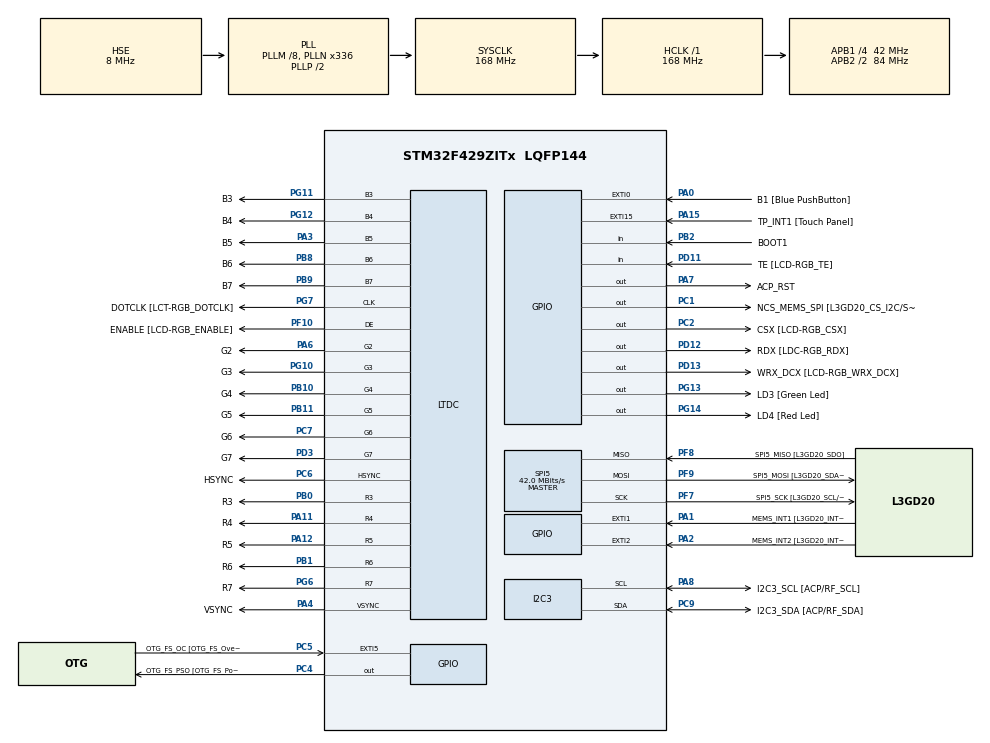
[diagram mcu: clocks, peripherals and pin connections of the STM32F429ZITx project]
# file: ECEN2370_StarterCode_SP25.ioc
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Mcu.Family=STM32F4
Mcu.Name=STM32F429ZITx
Mcu.Package=LQFP144
NVIC.PriorityGroup=NVIC_PRIORITYGROUP_0
NVIC.TIM2_IRQn=true\:0\:0\:false\:false\:true\:true\:true\:true
PA0/WKUP.GPIO_Label=B1 [Blue PushButton]
PA0/WKUP.GPIO_ModeDefaultEXTI=GPIO_MODE_EVT_RISING
PA0/WKUP.GPIO_PuPd=GPIO_NOPULL
PA0/WKUP.Signal=GPXTI0
PA1.GPIO_Label=MEMS_INT1 [L3GD20_INT1]
PA1.GPIO_ModeDefaultEXTI=GPIO_MODE_EVT_RISING
PA1.GPIO_PuPd=GPIO_NOPULL
PA1.Signal=GPXTI1
PA10.GPIO_Label=STLINK_TX [STM32F103CBT6_PA2]
PA10.Signal=USART1_RX
PA11.GPIO_Label=R4
PA11.GPIO_Mode=GPIO_MODE_AF_PP
PA11.GPIO_PuPd=GPIO_NOPULL
PA11.GPIO_Speed=GPIO_SPEED_FREQ_LOW
PA11.Mode=RGB565
PA11.Signal=LTDC_R4
PA12.GPIO_Label=R5
PA12.GPIO_Mode=GPIO_MODE_AF_PP
PA12.GPIO_PuPd=GPIO_NOPULL
PA12.GPIO_Speed=GPIO_SPEED_FREQ_LOW
PA12.Mode=RGB565
PA12.Signal=LTDC_R5
PA13.GPIO_Label=SWDIO
PA13.Signal=SYS_JTMS-SWDIO
PA14.GPIO_Label=SWCLK
PA14.Signal=SYS_JTCK-SWCLK
PA15.GPIO_Label=TP_INT1 [Touch Panel]
PA15.GPIO_ModeDefaultEXTI=GPIO_MODE_EVT_RISING
PA15.GPIO_PuPd=GPIO_NOPULL
PA15.Signal=GPXTI15
PA2.GPIO_Label=MEMS_INT2 [L3GD20_INT2]
PA2.GPIO_ModeDefaultEXTI=GPIO_MODE_EVT_RISING
PA2.GPIO_PuPd=GPIO_NOPULL
PA2.Signal=GPXTI2
PA3.GPIO_Label=B5
PA3.GPIO_Mode=GPIO_MODE_AF_PP
PA3.GPIO_PuPd=GPIO_NOPULL
PA3.GPIO_Speed=GPIO_SPEED_FREQ_LOW
PA3.Mode=RGB565
PA3.Signal=LTDC_B5
PA4.GPIO_Label=VSYNC
PA4.GPIO_Mode=GPIO_MODE_AF_PP
PA4.GPIO_PuPd=GPIO_NOPULL
PA4.GPIO_Speed=GPIO_SPEED_FREQ_LOW
PA4.Mode=RGB565
PA4.Signal=LTDC_VSYNC
PA6.GPIO_Label=G2
PA6.GPIO_Mode=GPIO_MODE_AF_PP
PA6.GPIO_PuPd=GPIO_NOPULL
PA6.GPIO_Speed=GPIO_SPEED_FREQ_LOW
PA6.Mode=RGB565
PA6.Signal=LTDC_G2
PA7.GPIO_Label=ACP_RST
PA7.GPIO_Mode=GPIO_MODE_OUTPUT_PP
PA7.GPIO_PuPd=GPIO_NOPULL
PA7.GPIO_Speed=GPIO_SPEED_FREQ_LOW
PA7.Signal=GPIO_Output
PA8.GPIO_Label=I2C3_SCL [ACP/RF_SCL]
PA8.GPIO_Mode=GPIO_MODE_AF_OD
PA8.GPIO_PuPd=GPIO_NOPULL
PA8.GPIO_Speed=GPIO_SPEED_FREQ_LOW
PA8.Mode=I2C
PA8.Signal=I2C3_SCL
PA9.GPIO_Label=STLINK_RX [STM32F103CBT6_PA3]
PA9.Signal=USART1_TX
PB0.GPIO_Label=R3
PB0.GPIO_Mode=GPIO_MODE_AF_PP
PB0.GPIO_PuPd=GPIO_NOPULL
PB0.GPIO_Speed=GPIO_SPEED_FREQ_LOW
PB0.Mode=RGB565
PB0.Signal=LTDC_R3
PB1.GPIO_Label=R6
PB1.GPIO_Mode=GPIO_MODE_AF_PP
PB1.GPIO_PuPd=GPIO_NOPULL
PB1.GPIO_Speed=GPIO_SPEED_FREQ_LOW
PB1.Mode=RGB565
PB1.Signal=LTDC_R6
PB10.GPIO_Label=G4
PB10.GPIO_Mode=GPIO_MODE_AF_PP
PB10.GPIO_PuPd=GPIO_NOPULL
PB10.GPIO_Speed=GPIO_SPEED_FREQ_LOW
PB10.Mode=RGB565
PB10.Signal=LTDC_G4
PB11.GPIO_Label=G5
PB11.GPIO_Mode=GPIO_MODE_AF_PP
PB11.GPIO_PuPd=GPIO_NOPULL
PB11.GPIO_Speed=GPIO_SPEED_FREQ_LOW
PB11.Mode=RGB565
PB11.Signal=LTDC_G5
PB12.GPIO_Label=OTG_HS_ID
PB12.GPIO_Mode=GPIO_MODE_AF_PP
PB12.GPIO_PuPd=GPIO_NOPULL
PB12.GPIO_Speed=GPIO_SPEED_FREQ_LOW
PB12.Signal=USB_OTG_HS_ID
PB13.GPIO_Label=VBUS_HS
PB13.GPIO_Mode=GPIO_MODE_INPUT
PB13.GPIO_PuPd=GPIO_NOPULL
PB13.Signal=USB_OTG_HS_VBUS
PB14.GPIO_Label=OTG_HS_DM
PB14.GPIO_Mode=GPIO_MODE_AF_PP
PB14.GPIO_PuPd=GPIO_NOPULL
PB14.GPIO_Speed=GPIO_SPEED_FREQ_LOW
PB14.Signal=USB_OTG_HS_DM
PB15.GPIO_Label=OTG_HS_DP
PB15.GPIO_Mode=GPIO_MODE_AF_PP
PB15.GPIO_PuPd=GPIO_NOPULL
PB15.GPIO_Speed=GPIO_SPEED_FREQ_LOW
PB15.Signal=USB_OTG_HS_DP
PB2/BOOT1.GPIO_Label=BOOT1
PB2/BOOT1.GPIO_Mode=GPIO_MODE_INPUT
PB2/BOOT1.GPIO_PuPd=GPIO_NOPULL
PB2/BOOT1.Signal=GPIO_Input
PB5.GPIO_Label=SDCKE1
PB5.GPIO_Mode=GPIO_MODE_AF_PP
PB5.GPIO_PuPd=GPIO_NOPULL
PB5.GPIO_Speed=GPIO_SPEED_FREQ_VERY_HIGH
PB5.Signal=FMC_SDCKE1
PB6.GPIO_Label=SDNE1 [SDRAM_CS]
PB6.GPIO_Mode=GPIO_MODE_AF_PP
PB6.GPIO_PuPd=GPIO_NOPULL
PB6.GPIO_Speed=GPIO_SPEED_FREQ_VERY_HIGH
PB6.Signal=FMC_SDNE1
PB8.GPIO_Label=B6
PB8.GPIO_Mode=GPIO_MODE_AF_PP
PB8.GPIO_PuPd=GPIO_NOPULL
PB8.GPIO_Speed=GPIO_SPEED_FREQ_LOW
PB8.Mode=RGB565
PB8.Signal=LTDC_B6
PB9.GPIO_Label=B7
PB9.GPIO_Mode=GPIO_MODE_AF_PP
PB9.GPIO_PuPd=GPIO_NOPULL
PB9.GPIO_Speed=GPIO_SPEED_FREQ_LOW
PB9.Mode=RGB565
PB9.Signal=LTDC_B7
PC0.GPIO_Label=SDNWE
PC0.GPIO_Mode=GPIO_MODE_AF_PP
PC0.GPIO_PuPd=GPIO_NOPULL
PC0.GPIO_Speed=GPIO_SPEED_FREQ_VERY_HIGH
PC0.Signal=FMC_SDNWE
PC1.GPIO_Label=NCS_MEMS_SPI [L3GD20_CS_I2C/SPI]
PC1.GPIO_Mode=GPIO_MODE_OUTPUT_PP
PC1.GPIO_PuPd=GPIO_NOPULL
PC1.GPIO_Speed=GPIO_SPEED_FREQ_LOW
PC1.Signal=GPIO_Output
PC10.GPIO_Label=R2
PC10.GPIO_Mode=GPIO_MODE_AF_PP
PC10.GPIO_PuPd=GPIO_NOPULL
PC10.GPIO_Speed=GPIO_SPEED_FREQ_LOW
PC10.Signal=LTDC_R2
PC14/OSC32_IN.GPIO_Label=PC14-OSC32_IN
PC14/OSC32_IN.Signal=RCC_OSC32_IN
PC15/OSC32_OUT.GPIO_Label=PC15-OSC32_OUT
PC15/OSC32_OUT.Signal=RCC_OSC32_OUT
PC2.GPIO_Label=CSX [LCD-RGB_CSX]
PC2.GPIO_Mode=GPIO_MODE_OUTPUT_PP
PC2.GPIO_PuPd=GPIO_NOPULL
PC2.GPIO_Speed=GPIO_SPEED_FREQ_LOW
PC2.Signal=GPIO_Output
PC4.GPIO_Label=OTG_FS_PSO [OTG_FS_PowerSwitchOn]
PC4.GPIO_Mode=GPIO_MODE_OUTPUT_PP
PC4.GPIO_PuPd=GPIO_NOPULL
PC4.GPIO_Speed=GPIO_SPEED_FREQ_LOW
PC4.Signal=GPIO_Output
PC5.GPIO_Label=OTG_FS_OC [OTG_FS_OverCurrent]
PC5.GPIO_ModeDefaultEXTI=GPIO_MODE_EVT_RISING
PC5.Signal=GPXTI5
PC6.GPIO_Label=HSYNC
PC6.GPIO_Mode=GPIO_MODE_AF_PP
PC6.GPIO_PuPd=GPIO_NOPULL
PC6.GPIO_Speed=GPIO_SPEED_FREQ_LOW
PC6.Mode=RGB565
PC6.Signal=LTDC_HSYNC
PC7.GPIO_Label=G6
PC7.GPIO_Mode=GPIO_MODE_AF_PP
PC7.GPIO_PuPd=GPIO_NOPULL
PC7.GPIO_Speed=GPIO_SPEED_FREQ_LOW
PC7.Mode=RGB565
PC7.Signal=LTDC_G6
PC9.GPIO_Label=I2C3_SDA [ACP/RF_SDA]
PC9.GPIO_Mode=GPIO_MODE_AF_OD
PC9.GPIO_PuPd=GPIO_NOPULL
PC9.GPIO_Speed=GPIO_SPEED_FREQ_LOW
PC9.Mode=I2C
PC9.Signal=I2C3_SDA
PD0.GPIO_Label=D2
PD0.GPIO_Mode=GPIO_MODE_AF_PP
PD0.GPIO_PuPd=GPIO_NOPULL
PD0.GPIO_Speed=GPIO_SPEED_FREQ_VERY_HIGH
PD0.Signal=FMC_D2_DA2
PD1.GPIO_Label=D3
PD1.GPIO_Mode=GPIO_MODE_AF_PP
PD1.GPIO_PuPd=GPIO_NOPULL
PD1.GPIO_Speed=GPIO_SPEED_FREQ_VERY_HIGH
PD1.Signal=FMC_D3_DA3
PD10.GPIO_Label=D15
PD10.GPIO_Mode=GPIO_MODE_AF_PP
PD10.GPIO_PuPd=GPIO_NOPULL
PD10.GPIO_Speed=GPIO_SPEED_FREQ_VERY_HIGH
PD10.Signal=FMC_D15_DA15
PD11.GPIO_Label=TE [LCD-RGB_TE]
PD11.GPIO_Mode=GPIO_MODE_INPUT
PD11.GPIO_PuPd=GPIO_NOPULL
PD11.Signal=GPIO_Input
PD12.GPIO_Label=RDX [LDC-RGB_RDX]
PD12.GPIO_Mode=GPIO_MODE_OUTPUT_PP
PD12.GPIO_PuPd=GPIO_NOPULL
PD12.GPIO_Speed=GPIO_SPEED_FREQ_LOW
PD12.Signal=GPIO_Output
PD13.GPIO_Label=WRX_DCX [LCD-RGB_WRX_DCX]
PD13.GPIO_Mode=GPIO_MODE_OUTPUT_PP
PD13.GPIO_PuPd=GPIO_NOPULL
PD13.GPIO_Speed=GPIO_SPEED_FREQ_LOW
PD13.Signal=GPIO_Output
PD14.GPIO_Label=D0
PD14.GPIO_Mode=GPIO_MODE_AF_PP
PD14.GPIO_PuPd=GPIO_NOPULL
PD14.GPIO_Speed=GPIO_SPEED_FREQ_VERY_HIGH
PD14.Signal=FMC_D0_DA0
PD15.GPIO_Label=D1
PD15.GPIO_Mode=GPIO_MODE_AF_PP
PD15.GPIO_PuPd=GPIO_NOPULL
PD15.GPIO_Speed=GPIO_SPEED_FREQ_VERY_HIGH
PD15.Signal=FMC_D1_DA1
PD3.GPIO_Label=G7
PD3.GPIO_Mode=GPIO_MODE_AF_PP
PD3.GPIO_PuPd=GPIO_NOPULL
PD3.GPIO_Speed=GPIO_SPEED_FREQ_LOW
PD3.Mode=RGB565
PD3.Signal=LTDC_G7
PD6.GPIO_Label=B2
PD6.GPIO_Mode=GPIO_MODE_AF_PP
PD6.GPIO_PuPd=GPIO_NOPULL
PD6.GPIO_Speed=GPIO_SPEED_FREQ_LOW
PD6.Signal=LTDC_B2
PD8.GPIO_Label=D13
PD8.GPIO_Mode=GPIO_MODE_AF_PP
PD8.GPIO_PuPd=GPIO_NOPULL
PD8.GPIO_Speed=GPIO_SPEED_FREQ_VERY_HIGH
PD8.Signal=FMC_D13_DA13
PD9.GPIO_Label=D14
PD9.GPIO_Mode=GPIO_MODE_AF_PP
PD9.GPIO_PuPd=GPIO_NOPULL
PD9.GPIO_Speed=GPIO_SPEED_FREQ_VERY_HIGH
PD9.Signal=FMC_D14_DA14
PE0.GPIO_Label=NBL0 [SDRAM_LDQM]
PE0.GPIO_Mode=GPIO_MODE_AF_PP
PE0.GPIO_PuPd=GPIO_NOPULL
PE0.GPIO_Speed=GPIO_SPEED_FREQ_VERY_HIGH
PE0.Signal=FMC_NBL0
PE1.GPIO_Label=NBL1 [SDRAM_UDQM]
PE1.GPIO_Mode=GPIO_MODE_AF_PP
PE1.GPIO_PuPd=GPIO_NOPULL
PE1.GPIO_Speed=GPIO_SPEED_FREQ_VERY_HIGH
PE1.Signal=FMC_NBL1
PE10.GPIO_Label=D7
PE10.GPIO_Mode=GPIO_MODE_AF_PP
PE10.GPIO_PuPd=GPIO_NOPULL
PE10.GPIO_Speed=GPIO_SPEED_FREQ_VERY_HIGH
PE10.Signal=FMC_D7_DA7
PE11.GPIO_Label=D8
PE11.GPIO_Mode=GPIO_MODE_AF_PP
PE11.GPIO_PuPd=GPIO_NOPULL
PE11.GPIO_Speed=GPIO_SPEED_FREQ_VERY_HIGH
PE11.Signal=FMC_D8_DA8
PE12.GPIO_Label=D9
PE12.GPIO_Mode=GPIO_MODE_AF_PP
PE12.GPIO_PuPd=GPIO_NOPULL
PE12.GPIO_Speed=GPIO_SPEED_FREQ_VERY_HIGH
PE12.Signal=FMC_D9_DA9
PE13.GPIO_Label=D10
PE13.GPIO_Mode=GPIO_MODE_AF_PP
PE13.GPIO_PuPd=GPIO_NOPULL
PE13.GPIO_Speed=GPIO_SPEED_FREQ_VERY_HIGH
PE13.Signal=FMC_D10_DA10
PE14.GPIO_Label=D11
PE14.GPIO_Mode=GPIO_MODE_AF_PP
PE14.GPIO_PuPd=GPIO_NOPULL
PE14.GPIO_Speed=GPIO_SPEED_FREQ_VERY_HIGH
PE14.Signal=FMC_D11_DA11
PE15.GPIO_Label=D12
PE15.GPIO_Mode=GPIO_MODE_AF_PP
PE15.GPIO_PuPd=GPIO_NOPULL
PE15.GPIO_Speed=GPIO_SPEED_FREQ_VERY_HIGH
PE15.Signal=FMC_D12_DA12
PE7.GPIO_Label=D4
PE7.GPIO_Mode=GPIO_MODE_AF_PP
PE7.GPIO_PuPd=GPIO_NOPULL
PE7.GPIO_Speed=GPIO_SPEED_FREQ_VERY_HIGH
PE7.Signal=FMC_D4_DA4
PE8.GPIO_Label=D5
PE8.GPIO_Mode=GPIO_MODE_AF_PP
PE8.GPIO_PuPd=GPIO_NOPULL
PE8.GPIO_Speed=GPIO_SPEED_FREQ_VERY_HIGH
PE8.Signal=FMC_D5_DA5
PE9.GPIO_Label=D6
PE9.GPIO_Mode=GPIO_MODE_AF_PP
PE9.GPIO_PuPd=GPIO_NOPULL
PE9.GPIO_Speed=GPIO_SPEED_FREQ_VERY_HIGH
PE9.Signal=FMC_D6_DA6
PF0.GPIO_Label=A0
PF0.GPIO_Mode=GPIO_MODE_AF_PP
PF0.GPIO_PuPd=GPIO_NOPULL
PF0.GPIO_Speed=GPIO_SPEED_FREQ_VERY_HIGH
PF0.Signal=FMC_A0
PF1.GPIO_Label=A1
PF1.GPIO_Mode=GPIO_MODE_AF_PP
PF1.GPIO_PuPd=GPIO_NOPULL
PF1.GPIO_Speed=GPIO_SPEED_FREQ_VERY_HIGH
PF1.Signal=FMC_A1
PF10.GPIO_Label=ENABLE [LCD-RGB_ENABLE]
PF10.GPIO_Mode=GPIO_MODE_AF_PP
PF10.GPIO_PuPd=GPIO_NOPULL
PF10.GPIO_Speed=GPIO_SPEED_FREQ_LOW
PF10.Mode=RGB565
PF10.Signal=LTDC_DE
PF11.GPIO_Label=SDNRAS
PF11.GPIO_Mode=GPIO_MODE_AF_PP
PF11.GPIO_PuPd=GPIO_NOPULL
PF11.GPIO_Speed=GPIO_SPEED_FREQ_VERY_HIGH
PF11.Signal=FMC_SDNRAS
PF12.GPIO_Label=A6
PF12.GPIO_Mode=GPIO_MODE_AF_PP
PF12.GPIO_PuPd=GPIO_NOPULL
PF12.GPIO_Speed=GPIO_SPEED_FREQ_VERY_HIGH
PF12.Signal=FMC_A6
PF13.GPIO_Label=A7
PF13.GPIO_Mode=GPIO_MODE_AF_PP
PF13.GPIO_PuPd=GPIO_NOPULL
PF13.GPIO_Speed=GPIO_SPEED_FREQ_VERY_HIGH
PF13.Signal=FMC_A7
PF14.GPIO_Label=A8
PF14.GPIO_Mode=GPIO_MODE_AF_PP
PF14.GPIO_PuPd=GPIO_NOPULL
PF14.GPIO_Speed=GPIO_SPEED_FREQ_VERY_HIGH
PF14.Signal=FMC_A8
PF15.GPIO_Label=A9
PF15.GPIO_Mode=GPIO_MODE_AF_PP
PF15.GPIO_PuPd=GPIO_NOPULL
PF15.GPIO_Speed=GPIO_SPEED_FREQ_VERY_HIGH
PF15.Signal=FMC_A9
PF2.GPIO_Label=A2
PF2.GPIO_Mode=GPIO_MODE_AF_PP
PF2.GPIO_PuPd=GPIO_NOPULL
PF2.GPIO_Speed=GPIO_SPEED_FREQ_VERY_HIGH
PF2.Signal=FMC_A2
PF3.GPIO_Label=A3
PF3.GPIO_Mode=GPIO_MODE_AF_PP
PF3.GPIO_PuPd=GPIO_NOPULL
PF3.GPIO_Speed=GPIO_SPEED_FREQ_VERY_HIGH
PF3.Signal=FMC_A3
PF4.GPIO_Label=A4
PF4.GPIO_Mode=GPIO_MODE_AF_PP
PF4.GPIO_PuPd=GPIO_NOPULL
PF4.GPIO_Speed=GPIO_SPEED_FREQ_VERY_HIGH
PF4.Signal=FMC_A4
PF5.GPIO_Label=A5
PF5.GPIO_Mode=GPIO_MODE_AF_PP
PF5.GPIO_PuPd=GPIO_NOPULL
PF5.GPIO_Speed=GPIO_SPEED_FREQ_VERY_HIGH
PF5.Signal=FMC_A5
PF7.GPIO_Label=SPI5_SCK [L3GD20_SCL/SPC]
PF7.GPIO_Mode=GPIO_MODE_AF_PP
PF7.GPIO_PuPd=GPIO_NOPULL
PF7.GPIO_Speed=GPIO_SPEED_FREQ_LOW
PF7.Mode=Full_Duplex_Master
PF7.Signal=SPI5_SCK
PF8.GPIO_Label=SPI5_MISO [L3GD20_SDO]
PF8.GPIO_Mode=GPIO_MODE_AF_PP
PF8.GPIO_PuPd=GPIO_NOPULL
PF8.GPIO_Speed=GPIO_SPEED_FREQ_LOW
PF8.Mode=Full_Duplex_Master
PF8.Signal=SPI5_MISO
PF9.GPIO_Label=SPI5_MOSI [L3GD20_SDA/SDI/SDO]
PF9.GPIO_Mode=GPIO_MODE_AF_PP
PF9.GPIO_PuPd=GPIO_NOPULL
PF9.GPIO_Speed=GPIO_SPEED_FREQ_LOW
PF9.Mode=Full_Duplex_Master
PF9.Signal=SPI5_MOSI
PG0.GPIO_Label=A10
PG0.GPIO_Mode=GPIO_MODE_AF_PP
PG0.GPIO_PuPd=GPIO_NOPULL
PG0.GPIO_Speed=GPIO_SPEED_FREQ_VERY_HIGH
PG0.Signal=FMC_A10
PG1.GPIO_Label=A11
PG1.GPIO_Mode=GPIO_MODE_AF_PP
PG1.GPIO_PuPd=GPIO_NOPULL
PG1.GPIO_Speed=GPIO_SPEED_FREQ_VERY_HIGH
PG1.Signal=FMC_A11
PG10.GPIO_Label=G3
PG10.GPIO_Mode=GPIO_MODE_AF_PP
PG10.GPIO_PuPd=GPIO_NOPULL
PG10.GPIO_Speed=GPIO_SPEED_FREQ_LOW
PG10.Mode=RGB565
PG10.Signal=LTDC_G3
PG11.GPIO_Label=B3
PG11.GPIO_Mode=GPIO_MODE_AF_PP
PG11.GPIO_PuPd=GPIO_NOPULL
PG11.GPIO_Speed=GPIO_SPEED_FREQ_LOW
PG11.Mode=RGB565
PG11.Signal=LTDC_B3
PG12.GPIO_Label=B4
PG12.GPIO_Mode=GPIO_MODE_AF_PP
PG12.GPIO_PuPd=GPIO_NOPULL
PG12.GPIO_Speed=GPIO_SPEED_FREQ_LOW
PG12.Mode=RGB565
PG12.Signal=LTDC_B4
PG13.GPIO_Label=LD3 [Green Led]
PG13.GPIO_Mode=GPIO_MODE_OUTPUT_PP
PG13.GPIO_PuPd=GPIO_NOPULL
PG13.GPIO_Speed=GPIO_SPEED_FREQ_LOW
PG13.Signal=GPIO_Output
PG14.GPIO_Label=LD4 [Red Led]
PG14.GPIO_Mode=GPIO_MODE_OUTPUT_PP
PG14.GPIO_PuPd=GPIO_NOPULL
PG14.GPIO_Speed=GPIO_SPEED_FREQ_LOW
PG14.Signal=GPIO_Output
PG15.GPIO_Label=SDNCAS
PG15.GPIO_Mode=GPIO_MODE_AF_PP
PG15.GPIO_PuPd=GPIO_NOPULL
PG15.GPIO_Speed=GPIO_SPEED_FREQ_VERY_HIGH
PG15.Signal=FMC_SDNCAS
PG4.GPIO_Label=BA0
PG4.GPIO_Mode=GPIO_MODE_AF_PP
PG4.GPIO_PuPd=GPIO_NOPULL
PG4.GPIO_Speed=GPIO_SPEED_FREQ_VERY_HIGH
PG4.Signal=FMC_A14_BA0
PG5.GPIO_Label=BA1
PG5.GPIO_Mode=GPIO_MODE_AF_PP
PG5.GPIO_PuPd=GPIO_NOPULL
PG5.GPIO_Speed=GPIO_SPEED_FREQ_VERY_HIGH
PG5.Signal=FMC_A15_BA1
PG6.GPIO_Label=R7
PG6.GPIO_Mode=GPIO_MODE_AF_PP
PG6.GPIO_PuPd=GPIO_NOPULL
PG6.GPIO_Speed=GPIO_SPEED_FREQ_LOW
PG6.Mode=RGB565
PG6.Signal=LTDC_R7
PG7.GPIO_Label=DOTCLK [LCT-RGB_DOTCLK]
PG7.GPIO_Mode=GPIO_MODE_AF_PP
PG7.GPIO_PuPd=GPIO_NOPULL
PG7.GPIO_Speed=GPIO_SPEED_FREQ_LOW
PG7.Mode=RGB565
PG7.Signal=LTDC_CLK
PG8.GPIO_Label=SDCLK
PG8.GPIO_Mode=GPIO_MODE_AF_PP
PG8.GPIO_PuPd=GPIO_NOPULL
PG8.GPIO_Speed=GPIO_SPEED_FREQ_VERY_HIGH
PG8.Signal=FMC_SDCLK
PH0/OSC_IN.GPIO_Label=PH0-OSC_IN
PH0/OSC_IN.Mode=HSE-External-Oscillator
PH0/OSC_IN.Signal=RCC_OSC_IN
PH1/OSC_OUT.GPIO_Label=PH1-OSC_OUT
PH1/OSC_OUT.Mode=HSE-External-Oscillator
PH1/OSC_OUT.Signal=RCC_OSC_OUT
ProjectManager.HeapSize=0x200
ProjectManager.StackSize=0x400
ProjectManager.TargetToolchain=STM32CubeIDE
RCC.48MHZClocksFreq_Value=48000000
RCC.AHBFreq_Value=168000000
RCC.APB1CLKDivider=RCC_HCLK_DIV4
RCC.APB1Freq_Value=42000000
RCC.APB1TimFreq_Value=84000000
RCC.APB2CLKDivider=RCC_HCLK_DIV2
RCC.APB2Freq_Value=84000000
RCC.APB2TimFreq_Value=168000000
RCC.CortexFreq_Value=168000000
RCC.HCLKFreq_Value=168000000
RCC.HSE_VALUE=8000000
RCC.HSI_VALUE=16000000
RCC.LSE_VALUE=32768
RCC.PLLM=8
RCC.PLLN=336
RCC.PLLQ=7
RCC.PLLSAIDivR=RCC_PLLSAIDIVR_16
RCC.PLLSAIN=200
RCC.PLLSourceVirtual=RCC_PLLSOURCE_HSE
RCC.SYSCLKFreq_VALUE=168000000
RCC.SYSCLKSource=RCC_SYSCLKSOURCE_PLLCLK
RCC.VCOOutputFreq_Value=336000000
SH.FMC_A0.0=FMC_A0
SH.FMC_A1.0=FMC_A1
SH.FMC_A10.0=FMC_A10
SH.FMC_A11.0=FMC_A11
SH.FMC_A14_BA0.0=FMC_BA0
SH.FMC_A15_BA1.0=FMC_BA1
SH.FMC_A2.0=FMC_A2
SH.FMC_A3.0=FMC_A3
SH.FMC_A4.0=FMC_A4
SH.FMC_A5.0=FMC_A5
SH.FMC_A6.0=FMC_A6
SH.FMC_A7.0=FMC_A7
SH.FMC_A8.0=FMC_A8
SH.FMC_A9.0=FMC_A9
SH.FMC_D0_DA0.0=FMC_D0
SH.FMC_D10_DA10.0=FMC_D10
SH.FMC_D11_DA11.0=FMC_D11
SH.FMC_D12_DA12.0=FMC_D12
SH.FMC_D13_DA13.0=FMC_D13
SH.FMC_D14_DA14.0=FMC_D14
SH.FMC_D15_DA15.0=FMC_D15
SH.FMC_D1_DA1.0=FMC_D1
SH.FMC_D2_DA2.0=FMC_D2
SH.FMC_D3_DA3.0=FMC_D3
SH.FMC_D4_DA4.0=FMC_D4
SH.FMC_D5_DA5.0=FMC_D5
SH.FMC_D6_DA6.0=FMC_D6
SH.FMC_D7_DA7.0=FMC_D7
SH.FMC_D8_DA8.0=FMC_D8
SH.FMC_D9_DA9.0=FMC_D9
SH.FMC_NBL0.0=FMC_NBL0
SH.FMC_NBL1.0=FMC_NBL1
SH.FMC_SDCLK.0=FMC_SDCLK
SH.FMC_SDNCAS.0=FMC_SDNCAS
SH.FMC_SDNRAS.0=FMC_SDNRAS
SH.FMC_SDNWE.0=FMC_SDNWE
SPI5.CalculateBaudRate=42.0 MBits/s
SPI5.Direction=SPI_DIRECTION_2LINES
SPI5.Mode=SPI_MODE_MASTER
SPI5.VirtualType=VM_MASTER
TIM2.Period=199
TIM2.Prescaler=8399
VP_RNG_VS_RNG.Mode=RNG_Activate
VP_TIM2_VS_ClockSourceINT.Mode=Internal
board=STM32F429I-DISC1

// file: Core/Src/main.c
/* USER CODE BEGIN Header */
/**
  ******************************************************************************
  * @file           : main.c
  * @brief          : Main program body
  ******************************************************************************
  * @attention
  *
  * Copyright (c) 2025 STMicroelectronics.
  * All rights reserved.
  *
  * This software is licensed AS-IS.
  *
  ******************************************************************************
  */
/* USER CODE END Header */
#include "main.h"
#include "board.h"
#include "game.h"
#include "ui.h"
#include "ApplicationCode.h"
#include "LCD_Driver.h"
#include "input.h"
#include "ai.h"

I2C_HandleTypeDef hi2c3;

LTDC_HandleTypeDef hltdc;

RNG_HandleTypeDef hrng;

SPI_HandleTypeDef hspi5;

TIM_HandleTypeDef htim2;

/* USER CODE BEGIN PV */
extern uint8_t  gameOver;
extern uint32_t startTime;
extern uint8_t  winsP1;
extern uint8_t  winsP2;

/* USER CODE END PV */

void SystemClock_Config(void);
static void MX_GPIO_Init(void);
static void MX_LTDC_Init(void);
static void MX_RNG_Init(void);
static void MX_TIM2_Init(void);
static void MX_SPI5_Init(void);
static void MX_I2C3_Init(void);

  volatile uint8_t flag_touchScan  = 0;   /* set every 20 ms  */
  volatile uint8_t flag_statusBar  = 0;   /* set every ≈240 ms*/
  #define MOVE_INITIAL_DELAY   300u     /* 0.3 s */
  #define MOVE_REPEAT_DELAY    120u     /* 0.12 s */

  static void ProcessTouchAndMoveSelector(void);

  static void ProcessTouchAndMoveSelector(void)
  {
      static uint8_t  touchHeld    = 0;
      static uint32_t nextMoveTick = 0;
      static uint8_t  dropHeld     = 0;

      STMPE811_TouchData t;
      uint8_t st = returnTouchStateAndLocation(&t);

      /* -------- left / right sweep -------- */
      if (st == STMPE811_State_Pressed)
      {
          t.x = LCD_PIXEL_WIDTH - 1 - t.x;

          if (HAL_GetTick() >= nextMoveTick)
          {
              if (t.x < LCD_PIXEL_WIDTH / 2)  { if (selectedCol > 0)        selectedCol--; }
              else                            { if (selectedCol < COLS - 1) selectedCol++; }

              nextMoveTick = HAL_GetTick() +
                             (touchHeld ? MOVE_REPEAT_DELAY : MOVE_INITIAL_DELAY);
              touchHeld = 1;
          }
      }
      else { touchHeld = 0; nextMoveTick = 0; }

      /* -------- push-button DROP --------- */
      if (IsDropPressed())
      {
          if (dropHeld == 0)
          {
              dropHeld = 1;
              int8_t row = DropToken(selectedCol);
              if (row >= 0)
              {
                  if (CheckWin(row, selectedCol))
                  {
                      if (currentPlayer == 1) { winsP1++; SetRoundResult(1); }
                      else                     { winsP2++; SetRoundResult(2); }
                      gameOver = 1;
                  }
                  else if (CheckDraw()) { SetRoundResult(0); gameOver = 1; }
                  else                  { currentPlayer = (currentPlayer == 1) ? 2 : 1; }
              }
          }
      }
      else dropHeld = 0;
  }

  int main(void)
  {
      HAL_Init();
      SystemClock_Config();
      MX_GPIO_Init();
      MX_LTDC_Init();
      MX_I2C3_Init();
      MX_RNG_Init();
      MX_TIM2_Init();
      MX_SPI5_Init();

      ApplicationInit();
      HAL_Delay(500);

      HAL_TIM_Base_Start_IT(&htim2);     /* 20 ms tick (PSC=8399, ARR=199) */

      ResetGame();
      winsP1 = winsP2 = 0;
      SetRoundResult(0);

      WaitForModeSelection();
      DrawBoard();
      DrawStatusBar();
      DrawHoverToken(selectedCol, currentPlayer);

      uint8_t  prevSelCol   = selectedCol;

      while (1)
      {
          if (flag_touchScan)
          {
              flag_touchScan = 0;
              ProcessTouchAndMoveSelector();
          }

          if (flag_statusBar)
          {
              flag_statusBar = 0;
              DrawStatusBar();
          }

          if (!gameOver && gameMode == 1 && currentPlayer == 2)
          {
              int8_t col = GetSmartAIMove();
              if (col >= 0)
              {
                  HAL_Delay(150);
                  int8_t row = DropToken(col);
                  if (CheckWin(row, col))            { winsP2++; SetRoundResult(2); gameOver = 1; }
                  else if (CheckDraw())              { SetRoundResult(0);          gameOver = 1; }
                  else                               { currentPlayer = 1; }
              }
          }

          if (prevSelCol != selectedCol)
          {
              ClearHoverToken(prevSelCol);
              DrawHoverToken(selectedCol, currentPlayer);
              prevSelCol = selectedCol;
          }

          if (gameOver)
          {
              DrawFinalScreen(GetElapsedTimeSeconds());
              WaitForRestartTap();

              ResetGame();
              SetRoundResult(0);
              DrawBoard();
              DrawStatusBar();
              DrawHoverToken(selectedCol, currentPlayer);

              prevSelCol   = selectedCol;

          }
      }
  }

void SystemClock_Config(void)
{
  RCC_OscInitTypeDef RCC_OscInitStruct = {0};
  RCC_ClkInitTypeDef RCC_ClkInitStruct = {0};

  /** Configure the main internal regulator output voltage
  */
  __HAL_RCC_PWR_CLK_ENABLE();
  __HAL_PWR_VOLTAGESCALING_CONFIG(PWR_REGULATOR_VOLTAGE_SCALE1);

  /** Initializes the RCC Oscillators according to the specified parameters
  * in the RCC_OscInitTypeDef structure.
  */
  RCC_OscInitStruct.OscillatorType = RCC_OSCILLATORTYPE_HSE;
  RCC_OscInitStruct.HSEState = RCC_HSE_ON;
  RCC_OscInitStruct.PLL.PLLState = RCC_PLL_ON;
  RCC_OscInitStruct.PLL.PLLSource = RCC_PLLSOURCE_HSE;
  RCC_OscInitStruct.PLL.PLLM = 8;
  RCC_OscInitStruct.PLL.PLLN = 336;
  RCC_OscInitStruct.PLL.PLLP = RCC_PLLP_DIV2;
  RCC_OscInitStruct.PLL.PLLQ = 7;
  if (HAL_RCC_OscConfig(&RCC_OscInitStruct) != HAL_OK)
  {
    Error_Handler();
  }

  /** Initializes the CPU, AHB and APB buses clocks
  */
  RCC_ClkInitStruct.ClockType = RCC_CLOCKTYPE_HCLK|RCC_CLOCKTYPE_SYSCLK
                              |RCC_CLOCKTYPE_PCLK1|RCC_CLOCKTYPE_PCLK2;
  RCC_ClkInitStruct.SYSCLKSource = RCC_SYSCLKSOURCE_PLLCLK;
  RCC_ClkInitStruct.AHBCLKDivider = RCC_SYSCLK_DIV1;
  RCC_ClkInitStruct.APB1CLKDivider = RCC_HCLK_DIV4;
  RCC_ClkInitStruct.APB2CLKDivider = RCC_HCLK_DIV2;

  if (HAL_RCC_ClockConfig(&RCC_ClkInitStruct, FLASH_LATENCY_5) != HAL_OK)
  {
    Error_Handler();
  }
}

static void MX_I2C3_Init(void)
{

  hi2c3.Instance = I2C3;
  hi2c3.Init.ClockSpeed = 100000;
  hi2c3.Init.DutyCycle = I2C_DUTYCYCLE_2;
  hi2c3.Init.OwnAddress1 = 0;
  hi2c3.Init.AddressingMode = I2C_ADDRESSINGMODE_7BIT;
  hi2c3.Init.DualAddressMode = I2C_DUALADDRESS_DISABLE;
  hi2c3.Init.OwnAddress2 = 0;
  hi2c3.Init.GeneralCallMode = I2C_GENERALCALL_DISABLE;
  hi2c3.Init.NoStretchMode = I2C_NOSTRETCH_DISABLE;
  if (HAL_I2C_Init(&hi2c3) != HAL_OK)
  {
    Error_Handler();
  }

  /** Configure Analogue filter
  */
  if (HAL_I2CEx_ConfigAnalogFilter(&hi2c3, I2C_ANALOGFILTER_ENABLE) != HAL_OK)
  {
    Error_Handler();
  }

  /** Configure Digital filter
  */
  if (HAL_I2CEx_ConfigDigitalFilter(&hi2c3, 0) != HAL_OK)
  {
    Error_Handler();
  }

}

static void MX_LTDC_Init(void)
{

  LTDC_LayerCfgTypeDef pLayerCfg = {0};
  LTDC_LayerCfgTypeDef pLayerCfg1 = {0};

  hltdc.Instance = LTDC;
  hltdc.Init.HSPolarity = LTDC_HSPOLARITY_AL;
  hltdc.Init.VSPolarity = LTDC_VSPOLARITY_AL;
  hltdc.Init.DEPolarity = LTDC_DEPOLARITY_AL;
  hltdc.Init.PCPolarity = LTDC_PCPOLARITY_IPC;
  hltdc.Init.HorizontalSync = 7;
  hltdc.Init.VerticalSync = 3;
  hltdc.Init.AccumulatedHBP = 14;
  hltdc.Init.AccumulatedVBP = 5;
  hltdc.Init.AccumulatedActiveW = 654;
  hltdc.Init.AccumulatedActiveH = 485;
  hltdc.Init.TotalWidth = 660;
  hltdc.Init.TotalHeigh = 487;
  hltdc.Init.Backcolor.Blue = 0;
  hltdc.Init.Backcolor.Green = 0;
  hltdc.Init.Backcolor.Red = 0;
  if (HAL_LTDC_Init(&hltdc) != HAL_OK)
  {
    Error_Handler();
  }
  pLayerCfg.WindowX0 = 0;
  pLayerCfg.WindowX1 = 0;
  pLayerCfg.WindowY0 = 0;
  pLayerCfg.WindowY1 = 0;
  pLayerCfg.PixelFormat = LTDC_PIXEL_FORMAT_ARGB8888;
  pLayerCfg.Alpha = 0;
  pLayerCfg.Alpha0 = 0;
  pLayerCfg.BlendingFactor1 = LTDC_BLENDING_FACTOR1_CA;
  pLayerCfg.BlendingFactor2 = LTDC_BLENDING_FACTOR2_CA;
  pLayerCfg.FBStartAdress = 0;
  pLayerCfg.ImageWidth = 0;
  pLayerCfg.ImageHeight = 0;
  pLayerCfg.Backcolor.Blue = 0;
  pLayerCfg.Backcolor.Green = 0;
  pLayerCfg.Backcolor.Red = 0;
  if (HAL_LTDC_ConfigLayer(&hltdc, &pLayerCfg, 0) != HAL_OK)
  {
    Error_Handler();
  }
  pLayerCfg1.WindowX0 = 0;
  pLayerCfg1.WindowX1 = 0;
  pLayerCfg1.WindowY0 = 0;
  pLayerCfg1.WindowY1 = 0;
  pLayerCfg1.PixelFormat = LTDC_PIXEL_FORMAT_ARGB8888;
  pLayerCfg1.Alpha = 0;
  pLayerCfg1.Alpha0 = 0;
  pLayerCfg1.BlendingFactor1 = LTDC_BLENDING_FACTOR1_CA;
  pLayerCfg1.BlendingFactor2 = LTDC_BLENDING_FACTOR2_CA;
  pLayerCfg1.FBStartAdress = 0;
  pLayerCfg1.ImageWidth = 0;
  pLayerCfg1.ImageHeight = 0;
  pLayerCfg1.Backcolor.Blue = 0;
  pLayerCfg1.Backcolor.Green = 0;
  pLayerCfg1.Backcolor.Red = 0;
  if (HAL_LTDC_ConfigLayer(&hltdc, &pLayerCfg1, 1) != HAL_OK)
  {
    Error_Handler();
  }

}

static void MX_RNG_Init(void)
{

  hrng.Instance = RNG;
  if (HAL_RNG_Init(&hrng) != HAL_OK)
  {
    Error_Handler();
  }

}

static void MX_SPI5_Init(void)
{

  /* SPI5 parameter configuration*/
  hspi5.Instance = SPI5;
  hspi5.Init.Mode = SPI_MODE_MASTER;
  hspi5.Init.Direction = SPI_DIRECTION_2LINES;
  hspi5.Init.DataSize = SPI_DATASIZE_8BIT;
  hspi5.Init.CLKPolarity = SPI_POLARITY_LOW;
  hspi5.Init.CLKPhase = SPI_PHASE_1EDGE;
  hspi5.Init.NSS = SPI_NSS_SOFT;
  hspi5.Init.BaudRatePrescaler = SPI_BAUDRATEPRESCALER_2;
  hspi5.Init.FirstBit = SPI_FIRSTBIT_MSB;
  hspi5.Init.TIMode = SPI_TIMODE_DISABLE;
  hspi5.Init.CRCCalculation = SPI_CRCCALCULATION_DISABLE;
  hspi5.Init.CRCPolynomial = 10;
  if (HAL_SPI_Init(&hspi5) != HAL_OK)
  {
    Error_Handler();
  }

}

static void MX_TIM2_Init(void)
{

  TIM_ClockConfigTypeDef sClockSourceConfig = {0};
  TIM_MasterConfigTypeDef sMasterConfig = {0};

  htim2.Instance = TIM2;
  htim2.Init.Prescaler = 8399;
  htim2.Init.CounterMode = TIM_COUNTERMODE_UP;
  htim2.Init.Period = 199;
  htim2.Init.ClockDivision = TIM_CLOCKDIVISION_DIV1;
  htim2.Init.AutoReloadPreload = TIM_AUTORELOAD_PRELOAD_DISABLE;
  if (HAL_TIM_Base_Init(&htim2) != HAL_OK)
  {
    Error_Handler();
  }
  sClockSourceConfig.ClockSource = TIM_CLOCKSOURCE_INTERNAL;
  if (HAL_TIM_ConfigClockSource(&htim2, &sClockSourceConfig) != HAL_OK)
  {
    Error_Handler();
  }
  sMasterConfig.MasterOutputTrigger = TIM_TRGO_RESET;
  sMasterConfig.MasterSlaveMode = TIM_MASTERSLAVEMODE_DISABLE;
  if (HAL_TIMEx_MasterConfigSynchronization(&htim2, &sMasterConfig) != HAL_OK)
  {
    Error_Handler();
  }

}

static void MX_GPIO_Init(void)
{
  GPIO_InitTypeDef GPIO_InitStruct = {0};

  /* GPIO Ports Clock Enable */
  __HAL_RCC_GPIOC_CLK_ENABLE();
  __HAL_RCC_GPIOF_CLK_ENABLE();
  __HAL_RCC_GPIOH_CLK_ENABLE();
  __HAL_RCC_GPIOA_CLK_ENABLE();
  __HAL_RCC_GPIOB_CLK_ENABLE();
  __HAL_RCC_GPIOG_CLK_ENABLE();
  __HAL_RCC_GPIOE_CLK_ENABLE();
  __HAL_RCC_GPIOD_CLK_ENABLE();

  /*Configure GPIO pin Output Level */
  HAL_GPIO_WritePin(GPIOC, NCS_MEMS_SPI_Pin|CSX_Pin|OTG_FS_PSO_Pin, GPIO_PIN_RESET);

  /*Configure GPIO pin Output Level */
  HAL_GPIO_WritePin(ACP_RST_GPIO_Port, ACP_RST_Pin, GPIO_PIN_RESET);

  /*Configure GPIO pin Output Level */
  HAL_GPIO_WritePin(GPIOD, RDX_Pin|WRX_DCX_Pin, GPIO_PIN_RESET);

  /*Configure GPIO pin Output Level */
  HAL_GPIO_WritePin(GPIOG, LD3_Pin|LD4_Pin, GPIO_PIN_RESET);

  /*Configure GPIO pins : A0_Pin A1_Pin A2_Pin A3_Pin
                           A4_Pin A5_Pin SDNRAS_Pin A6_Pin
                           A7_Pin A8_Pin A9_Pin */
  GPIO_InitStruct.Pin = A0_Pin|A1_Pin|A2_Pin|A3_Pin
                          |A4_Pin|A5_Pin|SDNRAS_Pin|A6_Pin
                          |A7_Pin|A8_Pin|A9_Pin;
  GPIO_InitStruct.Mode = GPIO_MODE_AF_PP;
  GPIO_InitStruct.Pull = GPIO_NOPULL;
  GPIO_InitStruct.Speed = GPIO_SPEED_FREQ_VERY_HIGH;
  GPIO_InitStruct.Alternate = GPIO_AF12_FMC;
  HAL_GPIO_Init(GPIOF, &GPIO_InitStruct);

  /*Configure GPIO pin : SDNWE_Pin */
  GPIO_InitStruct.Pin = SDNWE_Pin;
  GPIO_InitStruct.Mode = GPIO_MODE_AF_PP;
  GPIO_InitStruct.Pull = GPIO_NOPULL;
  GPIO_InitStruct.Speed = GPIO_SPEED_FREQ_VERY_HIGH;
  GPIO_InitStruct.Alternate = GPIO_AF12_FMC;
  HAL_GPIO_Init(SDNWE_GPIO_Port, &GPIO_InitStruct);

  /*Configure GPIO pins : NCS_MEMS_SPI_Pin CSX_Pin OTG_FS_PSO_Pin */
  GPIO_InitStruct.Pin = NCS_MEMS_SPI_Pin|CSX_Pin|OTG_FS_PSO_Pin;
  GPIO_InitStruct.Mode = GPIO_MODE_OUTPUT_PP;
  GPIO_InitStruct.Pull = GPIO_NOPULL;
  GPIO_InitStruct.Speed = GPIO_SPEED_FREQ_LOW;
  HAL_GPIO_Init(GPIOC, &GPIO_InitStruct);

  /*Configure GPIO pins : B1_Pin MEMS_INT1_Pin MEMS_INT2_Pin TP_INT1_Pin */
  GPIO_InitStruct.Pin = B1_Pin|MEMS_INT1_Pin|MEMS_INT2_Pin|TP_INT1_Pin;
  GPIO_InitStruct.Mode = GPIO_MODE_EVT_RISING;
  GPIO_InitStruct.Pull = GPIO_NOPULL;
  HAL_GPIO_Init(GPIOA, &GPIO_InitStruct);

  /*Configure GPIO pin : ACP_RST_Pin */
  GPIO_InitStruct.Pin = ACP_RST_Pin;
  GPIO_InitStruct.Mode = GPIO_MODE_OUTPUT_PP;
  GPIO_InitStruct.Pull = GPIO_NOPULL;
  GPIO_InitStruct.Speed = GPIO_SPEED_FREQ_LOW;
  HAL_GPIO_Init(ACP_RST_GPIO_Port, &GPIO_InitStruct);

  /*Configure GPIO pin : OTG_FS_OC_Pin */
  GPIO_InitStruct.Pin = OTG_FS_OC_Pin;
  GPIO_InitStruct.Mode = GPIO_MODE_EVT_RISING;
  GPIO_InitStruct.Pull = GPIO_NOPULL;
  HAL_GPIO_Init(OTG_FS_OC_GPIO_Port, &GPIO_InitStruct);

  /*Configure GPIO pin : BOOT1_Pin */
  GPIO_InitStruct.Pin = BOOT1_Pin;
  GPIO_InitStruct.Mode = GPIO_MODE_INPUT;
  GPIO_InitStruct.Pull = GPIO_NOPULL;
  HAL_GPIO_Init(BOOT1_GPIO_Port, &GPIO_InitStruct);

  /*Configure GPIO pins : A10_Pin A11_Pin BA0_Pin BA1_Pin
                           SDCLK_Pin SDNCAS_Pin */
  GPIO_InitStruct.Pin = A10_Pin|A11_Pin|BA0_Pin|BA1_Pin
                          |SDCLK_Pin|SDNCAS_Pin;
  GPIO_InitStruct.Mode = GPIO_MODE_AF_PP;
  GPIO_InitStruct.Pull = GPIO_NOPULL;
  GPIO_InitStruct.Speed = GPIO_SPEED_FREQ_VERY_HIGH;
  GPIO_InitStruct.Alternate = GPIO_AF12_FMC;
  HAL_GPIO_Init(GPIOG, &GPIO_InitStruct);

  /*Configure GPIO pins : D4_Pin D5_Pin D6_Pin D7_Pin
                           D8_Pin D9_Pin D10_Pin D11_Pin
                           D12_Pin NBL0_Pin NBL1_Pin */
  GPIO_InitStruct.Pin = D4_Pin|D5_Pin|D6_Pin|D7_Pin
                          |D8_Pin|D9_Pin|D10_Pin|D11_Pin
                          |D12_Pin|NBL0_Pin|NBL1_Pin;
  GPIO_InitStruct.Mode = GPIO_MODE_AF_PP;
  GPIO_InitStruct.Pull = GPIO_NOPULL;
  GPIO_InitStruct.Speed = GPIO_SPEED_FREQ_VERY_HIGH;
  GPIO_InitStruct.Alternate = GPIO_AF12_FMC;
  HAL_GPIO_Init(GPIOE, &GPIO_InitStruct);

  /*Configure GPIO pins : OTG_HS_ID_Pin OTG_HS_DM_Pin OTG_HS_DP_Pin */
  GPIO_InitStruct.Pin = OTG_HS_ID_Pin|OTG_HS_DM_Pin|OTG_HS_DP_Pin;
  GPIO_InitStruct.Mode = GPIO_MODE_AF_PP;
  GPIO_InitStruct.Pull = GPIO_NOPULL;
  GPIO_InitStruct.Speed = GPIO_SPEED_FREQ_LOW;
  GPIO_InitStruct.Alternate = GPIO_AF12_OTG_HS_FS;
  HAL_GPIO_Init(GPIOB, &GPIO_InitStruct);

  /*Configure GPIO pin : VBUS_HS_Pin */
  GPIO_InitStruct.Pin = VBUS_HS_Pin;
  GPIO_InitStruct.Mode = GPIO_MODE_INPUT;
  GPIO_InitStruct.Pull = GPIO_NOPULL;
  HAL_GPIO_Init(VBUS_HS_GPIO_Port, &GPIO_InitStruct);

  /*Configure GPIO pins : D13_Pin D14_Pin D15_Pin D0_Pin
                           D1_Pin D2_Pin D3_Pin */
  GPIO_InitStruct.Pin = D13_Pin|D14_Pin|D15_Pin|D0_Pin
                          |D1_Pin|D2_Pin|D3_Pin;
  GPIO_InitStruct.Mode = GPIO_MODE_AF_PP;
  GPIO_InitStruct.Pull = GPIO_NOPULL;
  GPIO_InitStruct.Speed = GPIO_SPEED_FREQ_VERY_HIGH;
  GPIO_InitStruct.Alternate = GPIO_AF12_FMC;
  HAL_GPIO_Init(GPIOD, &GPIO_InitStruct);

  /*Configure GPIO pin : TE_Pin */
  GPIO_InitStruct.Pin = TE_Pin;
  GPIO_InitStruct.Mode = GPIO_MODE_INPUT;
  GPIO_InitStruct.Pull = GPIO_NOPULL;
  HAL_GPIO_Init(TE_GPIO_Port, &GPIO_InitStruct);

  /*Configure GPIO pins : RDX_Pin WRX_DCX_Pin */
  GPIO_InitStruct.Pin = RDX_Pin|WRX_DCX_Pin;
  GPIO_InitStruct.Mode = GPIO_MODE_OUTPUT_PP;
  GPIO_InitStruct.Pull = GPIO_NOPULL;
  GPIO_InitStruct.Speed = GPIO_SPEED_FREQ_LOW;
  HAL_GPIO_Init(GPIOD, &GPIO_InitStruct);

  /*Configure GPIO pins : STLINK_RX_Pin STLINK_TX_Pin */
  GPIO_InitStruct.Pin = STLINK_RX_Pin|STLINK_TX_Pin;
  GPIO_InitStruct.Mode = GPIO_MODE_AF_PP;
  GPIO_InitStruct.Pull = GPIO_NOPULL;
  GPIO_InitStruct.Speed = GPIO_SPEED_FREQ_VERY_HIGH;
  GPIO_InitStruct.Alternate = GPIO_AF7_USART1;
  HAL_GPIO_Init(GPIOA, &GPIO_InitStruct);

  /*Configure GPIO pins : LD3_Pin LD4_Pin */
  GPIO_InitStruct.Pin = LD3_Pin|LD4_Pin;
  GPIO_InitStruct.Mode = GPIO_MODE_OUTPUT_PP;
  GPIO_InitStruct.Pull = GPIO_NOPULL;
  GPIO_InitStruct.Speed = GPIO_SPEED_FREQ_LOW;
  HAL_GPIO_Init(GPIOG, &GPIO_InitStruct);

  /*Configure GPIO pins : SDCKE1_Pin SDNE1_Pin */
  GPIO_InitStruct.Pin = SDCKE1_Pin|SDNE1_Pin;
  GPIO_InitStruct.Mode = GPIO_MODE_AF_PP;
  GPIO_InitStruct.Pull = GPIO_NOPULL;
  GPIO_InitStruct.Speed = GPIO_SPEED_FREQ_VERY_HIGH;
  GPIO_InitStruct.Alternate = GPIO_AF12_FMC;
  HAL_GPIO_Init(GPIOB, &GPIO_InitStruct);

}

/* USER CODE BEGIN 4 */
extern volatile uint8_t flag_touchScan;
extern volatile uint8_t flag_statusBar;

void HAL_TIM_PeriodElapsedCallback(TIM_HandleTypeDef *htim)
{
    if (htim->Instance == TIM2)
    {
        static uint8_t cnt = 0;

        flag_touchScan = 1;          // every 20 ms

        if (++cnt >= 12)             // 12 × 20 ms ≈ 240 ms
        {
            cnt = 0;
            flag_statusBar = 1;      // slower job
        }
    }
}
/* USER CODE END 4 */

void Error_Handler(void)
{
  __disable_irq();
  while (1)
  {
  }
}
